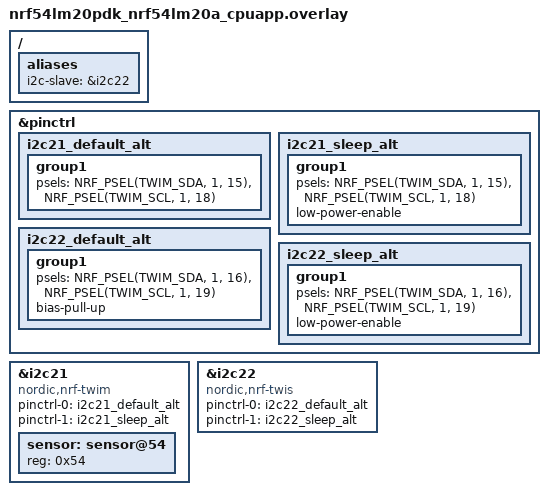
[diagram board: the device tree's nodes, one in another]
/*
 * Two loopbacks are required:
 * P1.15 - P1.16
 * P1.18 - P1.19
 */


/ {
	aliases {
		i2c-slave = &i2c22;
	};
};

&pinctrl {
	i2c21_default_alt: i2c21_default_alt {
		group1 {
			psels = <NRF_PSEL(TWIM_SDA, 1, 15)>,
				<NRF_PSEL(TWIM_SCL, 1, 18)>;
		};
	};

	i2c21_sleep_alt: i2c21_sleep_alt {
		group1 {
			psels = <NRF_PSEL(TWIM_SDA, 1, 15)>,
				<NRF_PSEL(TWIM_SCL, 1, 18)>;
			low-power-enable;
		};
	};

	i2c22_default_alt: i2c22_default_alt {
		group1 {
			psels = <NRF_PSEL(TWIM_SDA, 1, 16)>,
				<NRF_PSEL(TWIM_SCL, 1, 19)>;
			bias-pull-up;
		};
	};

	i2c22_sleep_alt: i2c22_sleep_alt {
		group1 {
			psels = <NRF_PSEL(TWIM_SDA, 1, 16)>,
				<NRF_PSEL(TWIM_SCL, 1, 19)>;
			low-power-enable;
		};
	};
};

&i2c21 {
	compatible = "nordic,nrf-twim";
	status = "okay";
	pinctrl-0 = <&i2c21_default_alt>;
	pinctrl-1 = <&i2c21_sleep_alt>;
	pinctrl-names = "default", "sleep";
	sensor: sensor@54 {
		reg = <0x54>;
	};
};

&i2c22 {
	compatible = "nordic,nrf-twis";
	status = "okay";
	pinctrl-0 = <&i2c22_default_alt>;
	pinctrl-1 = <&i2c22_sleep_alt>;
	pinctrl-names = "default", "sleep";
};
